# PIC32MZ2048EFH064 register map
Vendor: Microchip
Registers are 32-bit, read-write, reset 0x0 unless marked. A register's access mark holds for its fields unless they carry their own. Addresses are absolute, and some are shared; only a register's first bit layout is shown; [hi:lo] are bit positions; {n}, {i} and the like mark numbered series.

## CMP1
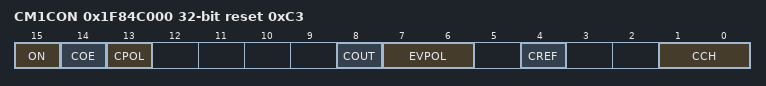
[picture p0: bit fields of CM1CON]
0x1F84C000 CM1CON reset 0xC3
  [15] ON, [14] COE, [13] CPOL, [8] COUT, [7:6] EVPOL, [4] CREF, [1:0] CCH

## CMP2
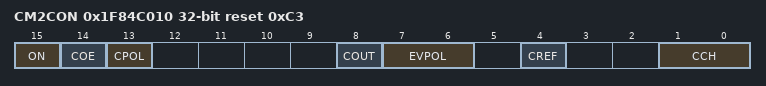
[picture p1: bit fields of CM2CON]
0x1F84C010 CM2CON reset 0xC3
  [15] ON, [14] COE, [13] CPOL, [8] COUT, [7:6] EVPOL, [4] CREF, [1:0] CCH

## cmp_control_pb
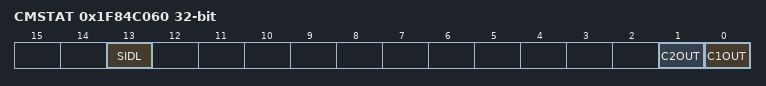
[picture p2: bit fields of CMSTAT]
0x1F84C060 CMSTAT
  [13] SIDL, [1] C2OUT ro, [0] C1OUT ro

## gpio_ports_upb
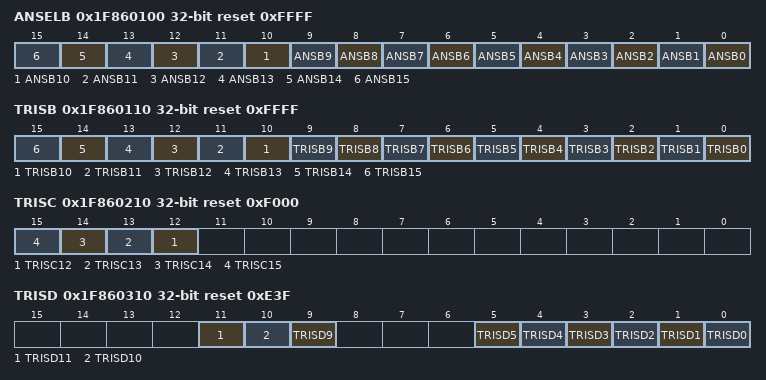
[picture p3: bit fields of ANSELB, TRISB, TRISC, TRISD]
0x1F860100 ANSELB reset 0xFFFF
  [n] ANSB{n} (n=0..15)
0x1F860110 TRISB reset 0xFFFF
  [n] TRISB{n} (n=0..15)
0x1F860210 TRISC reset 0xF000
  [n] TRISC{n} (n=12..15)
0x1F860310 TRISD reset 0xE3F
  [11] TRISD11, [10] TRISD10, [9] TRISD9, [n] TRISD{n} (n=0..5)
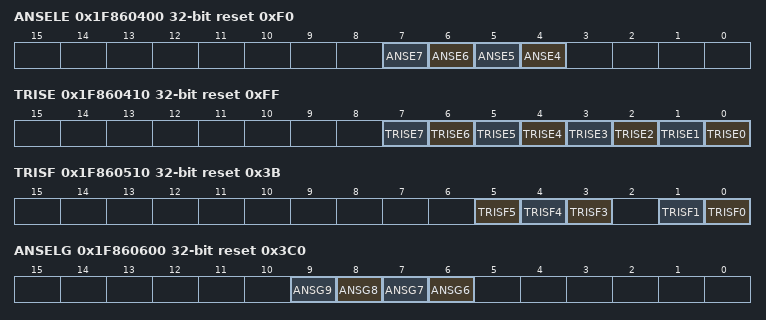
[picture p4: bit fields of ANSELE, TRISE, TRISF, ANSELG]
0x1F860400 ANSELE reset 0xF0
  [n] ANSE{n} (n=4..7)
0x1F860410 TRISE reset 0xFF
  [n] TRISE{n} (n=0..7)
0x1F860510 TRISF reset 0x3B
  [5] TRISF5, [4] TRISF4, [3] TRISF3, [1] TRISF1, [0] TRISF0
0x1F860600 ANSELG reset 0x3C0
  [n] ANSG{n} (n=6..9)
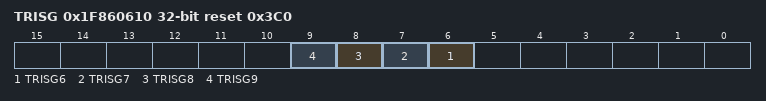
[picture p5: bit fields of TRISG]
0x1F860610 TRISG reset 0x3C0
  [n] TRISG{n} (n=6..9)

## PORTB
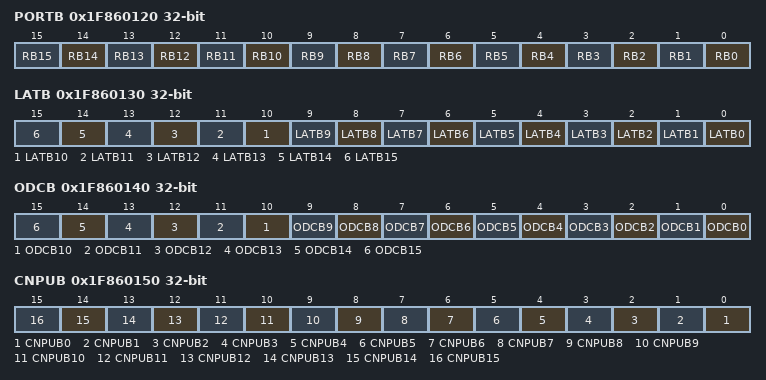
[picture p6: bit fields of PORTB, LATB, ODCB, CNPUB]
0x1F860120 PORTB reset not defined — (power-on value ----------------xxxxxxxxxxxxxxxx)
  [n] RB{n} (n=0..15)
0x1F860130 LATB reset not defined — (power-on value ----------------xxxxxxxxxxxxxxxx)
  [n] LATB{n} (n=0..15)
0x1F860140 ODCB
  [n] ODCB{n} (n=0..15)
0x1F860150 CNPUB
  [n] CNPUB{n} (n=0..15)
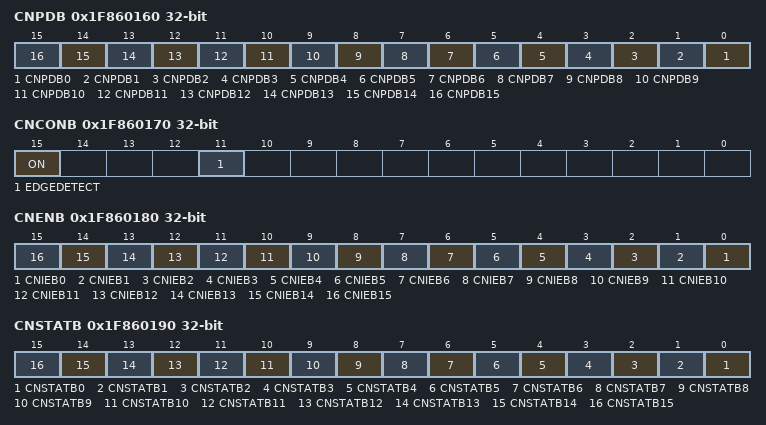
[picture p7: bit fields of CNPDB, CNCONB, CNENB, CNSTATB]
0x1F860160 CNPDB
  [n] CNPDB{n} (n=0..15)
0x1F860170 CNCONB
  [15] ON, [11] EDGEDETECT
0x1F860180 CNENB
  [n] CNIEB{n} (n=0..15)
0x1F860190 CNSTATB
  [n] CNSTATB{n} (n=0..15)
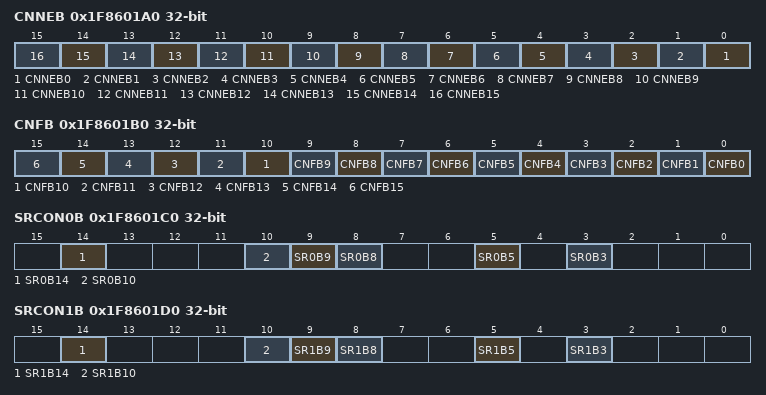
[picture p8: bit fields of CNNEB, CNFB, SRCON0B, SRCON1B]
0x1F8601A0 CNNEB
  [n] CNNEB{n} (n=0..15)
0x1F8601B0 CNFB
  [n] CNFB{n} (n=0..15)
0x1F8601C0 SRCON0B
  [14] SR0B14, [10] SR0B10, [9] SR0B9, [8] SR0B8, [5] SR0B5, [3] SR0B3
0x1F8601D0 SRCON1B
  [14] SR1B14, [10] SR1B10, [9] SR1B9, [8] SR1B8, [5] SR1B5, [3] SR1B3

## PORTC
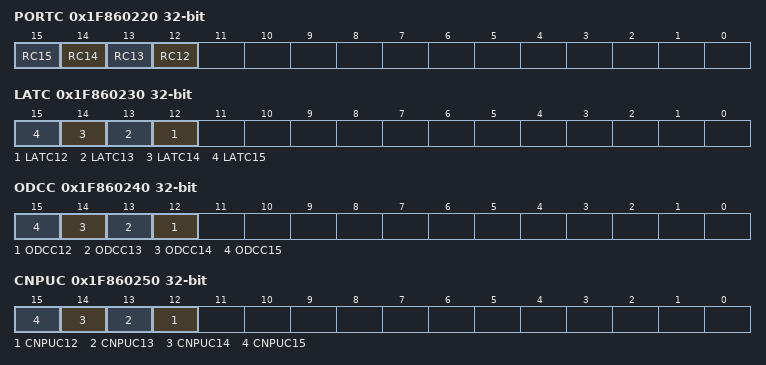
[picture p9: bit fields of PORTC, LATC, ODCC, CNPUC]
0x1F860220 PORTC reset not defined — (power-on value ----------------xxxx------------)
  [n] RC{n} (n=12..15)
0x1F860230 LATC reset not defined — (power-on value ----------------xxxx------------)
  [n] LATC{n} (n=12..15)
0x1F860240 ODCC
  [n] ODCC{n} (n=12..15)
0x1F860250 CNPUC
  [n] CNPUC{n} (n=12..15)
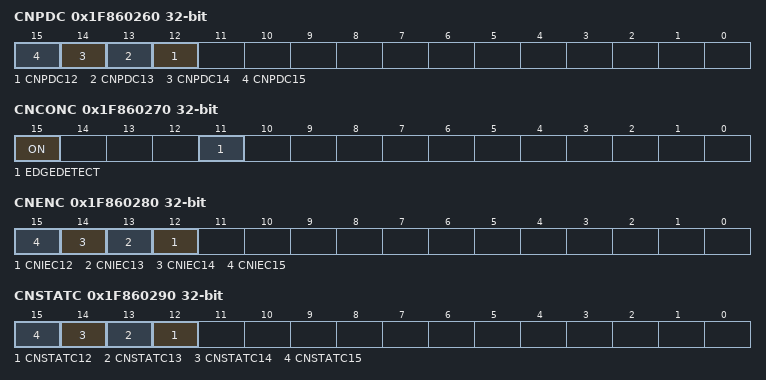
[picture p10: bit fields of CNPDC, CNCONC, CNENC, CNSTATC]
0x1F860260 CNPDC
  [n] CNPDC{n} (n=12..15)
0x1F860270 CNCONC
  [15] ON, [11] EDGEDETECT
0x1F860280 CNENC
  [n] CNIEC{n} (n=12..15)
0x1F860290 CNSTATC
  [n] CNSTATC{n} (n=12..15)
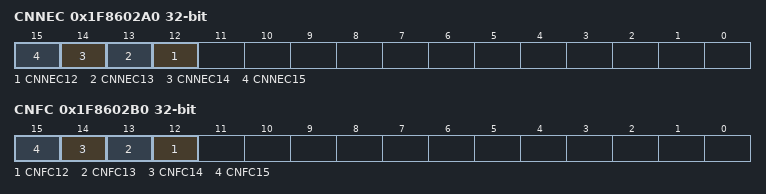
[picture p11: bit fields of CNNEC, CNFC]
0x1F8602A0 CNNEC
  [n] CNNEC{n} (n=12..15)
0x1F8602B0 CNFC
  [n] CNFC{n} (n=12..15)

## PORTD
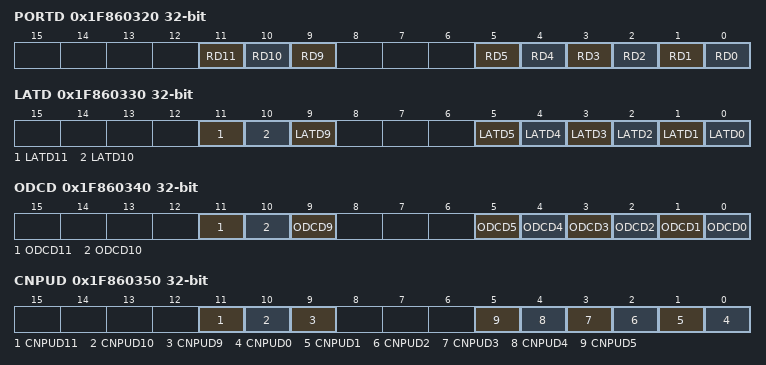
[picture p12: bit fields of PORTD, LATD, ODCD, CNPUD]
0x1F860320 PORTD reset not defined — (power-on value --------------------xxx---xxxxxx)
  [11] RD11, [10] RD10, [9] RD9, [n] RD{n} (n=0..5)
0x1F860330 LATD reset not defined — (power-on value --------------------xxx---xxxxxx)
  [11] LATD11, [10] LATD10, [9] LATD9, [n] LATD{n} (n=0..5)
0x1F860340 ODCD
  [11] ODCD11, [10] ODCD10, [9] ODCD9, [n] ODCD{n} (n=0..5)
0x1F860350 CNPUD
  [11] CNPUD11, [10] CNPUD10, [9] CNPUD9, [n] CNPUD{n} (n=0..5)
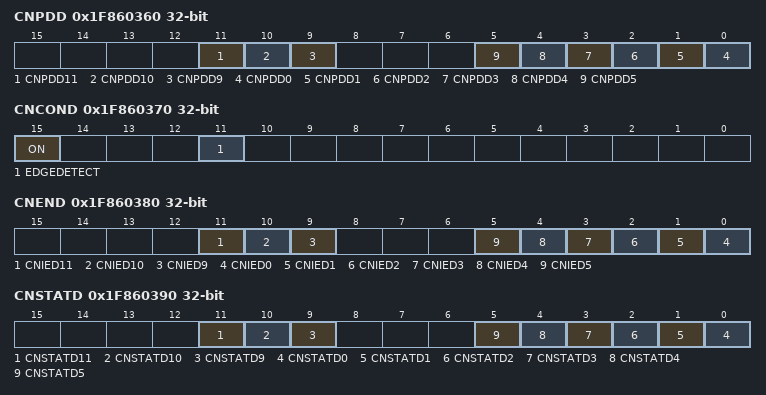
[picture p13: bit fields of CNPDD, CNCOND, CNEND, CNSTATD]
0x1F860360 CNPDD
  [11] CNPDD11, [10] CNPDD10, [9] CNPDD9, [n] CNPDD{n} (n=0..5)
0x1F860370 CNCOND
  [15] ON, [11] EDGEDETECT
0x1F860380 CNEND
  [11] CNIED11, [10] CNIED10, [9] CNIED9, [n] CNIED{n} (n=0..5)
0x1F860390 CNSTATD
  [11] CNSTATD11, [10] CNSTATD10, [9] CNSTATD9, [n] CNSTATD{n} (n=0..5)
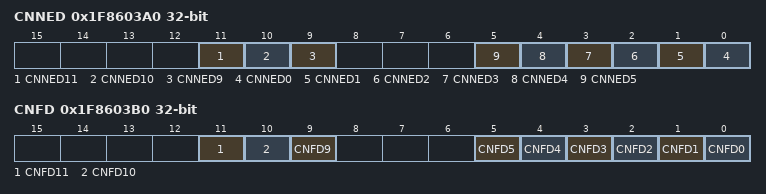
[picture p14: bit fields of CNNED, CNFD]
0x1F8603A0 CNNED
  [11] CNNED11, [10] CNNED10, [9] CNNED9, [n] CNNED{n} (n=0..5)
0x1F8603B0 CNFD
  [11] CNFD11, [10] CNFD10, [9] CNFD9, [n] CNFD{n} (n=0..5)

## PORTE
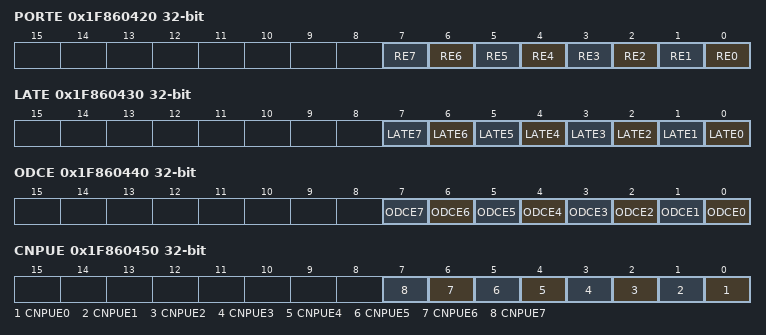
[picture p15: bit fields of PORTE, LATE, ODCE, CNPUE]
0x1F860420 PORTE reset not defined — (power-on value ------------------------xxxxxxxx)
  [n] RE{n} (n=0..7)
0x1F860430 LATE reset not defined — (power-on value ------------------------xxxxxxxx)
  [n] LATE{n} (n=0..7)
0x1F860440 ODCE
  [n] ODCE{n} (n=0..7)
0x1F860450 CNPUE
  [n] CNPUE{n} (n=0..7)
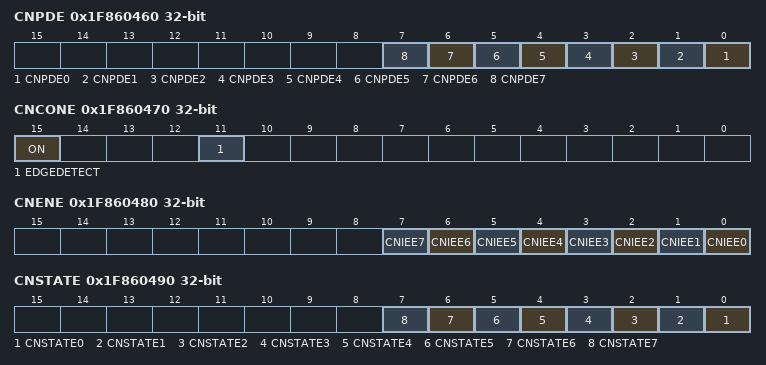
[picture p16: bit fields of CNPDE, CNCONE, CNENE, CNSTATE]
0x1F860460 CNPDE
  [n] CNPDE{n} (n=0..7)
0x1F860470 CNCONE
  [15] ON, [11] EDGEDETECT
0x1F860480 CNENE
  [n] CNIEE{n} (n=0..7)
0x1F860490 CNSTATE
  [n] CNSTATE{n} (n=0..7)
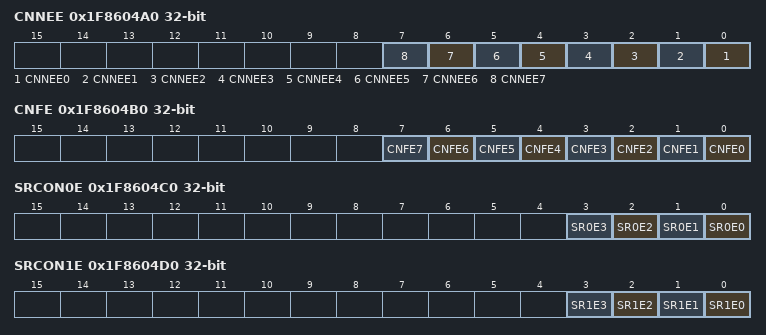
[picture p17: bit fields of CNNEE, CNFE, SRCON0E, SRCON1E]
0x1F8604A0 CNNEE
  [n] CNNEE{n} (n=0..7)
0x1F8604B0 CNFE
  [n] CNFE{n} (n=0..7)
0x1F8604C0 SRCON0E
  [n] SR0E{n} (n=0..3)
0x1F8604D0 SRCON1E
  [n] SR1E{n} (n=0..3)
